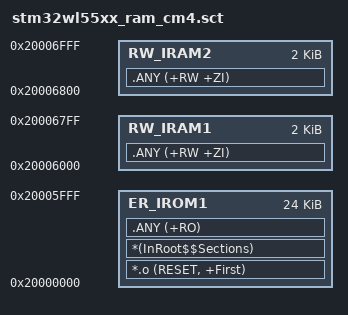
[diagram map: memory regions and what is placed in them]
; *************************************************************
; *** Scatter-Loading Description File generated by uVision ***
; *************************************************************

LR_IROM1 0x20000000 0x00006000  {    ; load region size_region
  ER_IROM1 0x20000000 0x00006000  {  ; load address = execution address
   *.o (RESET, +First)
   *(InRoot$$Sections)
   .ANY (+RO)
  }
  RW_IRAM1 0x20006000 0x00000800  {  ; RW data
   .ANY (+RW +ZI)
  }
  RW_IRAM2 0x20006800 0x00000800  {
   .ANY (+RW +ZI)
  }
}

